# MK22FA12 register map
Vendor: Freescale Semiconductor, Inc.; Series: Kinetis_K; File version: 1.6
CPU: CM4 r0p1, little endian, no MPU, FPU, VTOR, 4 interrupt priority bits
Registers are 32-bit, read-write, reset 0x0 unless marked. A register's access mark holds for its fields unless they carry their own. Offsets are from the block's base; [hi:lo] are bit positions; {n}, {i} and the like mark numbered series; 'fields as' and 'values as' point back to an identical list.

## SPI0 — Serial Peripheral Interface
Base 0x4002C000; register names take the prefix SPI0_
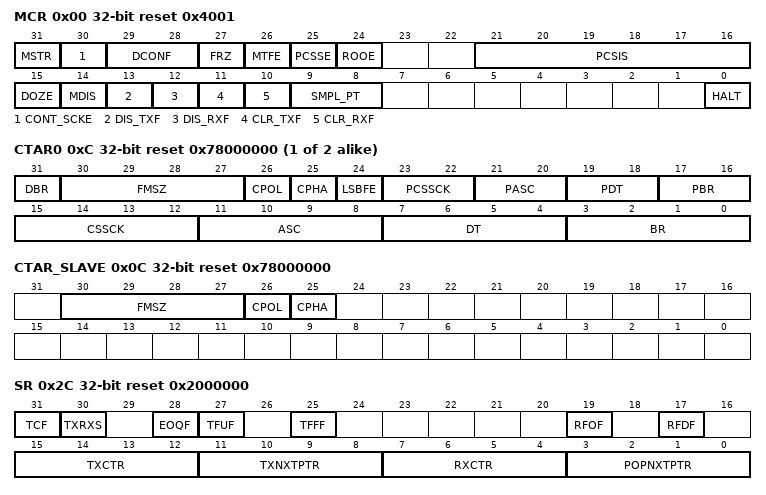
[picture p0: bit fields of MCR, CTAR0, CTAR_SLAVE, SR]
0x00 MCR reset 0x4001 — Module Configuration Register
  [31] MSTR — Master/Slave Mode Select
    0=Enables Slave mode; 1=Enables Master mode
  [30] CONT_SCKE — Continuous SCK Enable
    0=Continuous SCK disabled; 1=Continuous SCK enabled
  [29:28] DCONF ro — SPI Configuration.
    0=SPI
  [27] FRZ — Freeze
    0=Do not halt serial transfers in Debug mode; 1=Halt serial transfers in Debug mode
  [26] MTFE — Modified Timing Format Enable
    0=Modified SPI transfer format disabled; 1=Modified SPI transfer format enabled
  [25] PCSSE — Peripheral Chip Select Strobe Enable
    0=PCS5/ PCSS is used as the Peripheral Chip Select[5] signal; 1=PCS5/ PCSS is used as an active-low PCS Strobe signal
  [24] ROOE — Receive FIFO Overflow Overwrite Enable
    0=Incoming data is ignored; 1=Incoming data is shifted into the shift register
  [21:16] PCSIS — Peripheral Chip Select x Inactive State
    0=The inactive state of PCSx is low; 1=The inactive state of PCSx is high
  [15] DOZE — Doze Enable
    0=Doze mode has no effect on the module; 1=Doze mode disables the module
  [14] MDIS — Module Disable
    0=Enables the module clocks; 1=Allows external logic to disable the module clocks
  [13] DIS_TXF — Disable Transmit FIFO
    0=TX FIFO is enabled; 1=TX FIFO is disabled
  [12] DIS_RXF — Disable Receive FIFO
    0=RX FIFO is enabled; 1=RX FIFO is disabled
  [11] CLR_TXF wo — Clear TX FIFO
    0=Do not clear the TX FIFO counter; 1=Clear the TX FIFO counter
  [10] CLR_RXF wo
    0=Do not clear the RX FIFO counter; 1=Clear the RX FIFO counter
  [9:8] SMPL_PT — Sample Point
    0=0 protocol clock cycles between SCK edge and SIN sample; 1=1 protocol clock cycle between SCK edge and SIN sample; 2=2 protocol clock cycles between SCK edge and SIN sample
  [0] HALT
    0=Start transfers; 1=Stop transfers
0x08 TCR — Transfer Count Register
  [31:16] SPI_TCNT — SPI Transfer Counter
{0xC+4i} CTAR{i} (i=0..1) reset 0x78000000 (SPI0 view) — Clock and Transfer Attributes Register (In Master Mode)
  [31] DBR — Double Baud Rate
    0=The baud rate is computed normally with a 50/50 duty cycle; 1=The baud rate is doubled with the duty cycle depending on the Baud Rate Prescaler
  [30:27] FMSZ — Frame Size
  [26] CPOL — Clock Polarity
    0=The inactive state value of SCK is low; 1=The inactive state value of SCK is high
  [25] CPHA — Clock Phase
    0=Data is captured on the leading edge of SCK and changed on the following edge; 1=Data is changed on the leading edge of SCK and captured on the following edge
  [24] LSBFE — LSB First
    0=Data is transferred MSB first; 1=Data is transferred LSB first
  [23:22] PCSSCK — PCS to SCK Delay Prescaler
    0=PCS to SCK Prescaler value is 1; 1=PCS to SCK Prescaler value is 3; 2=PCS to SCK Prescaler value is 5; 3=PCS to SCK Prescaler value is 7
  [21:20] PASC — After SCK Delay Prescaler
    0=Delay after Transfer Prescaler value is 1; 1=Delay after Transfer Prescaler value is 3; 2=Delay after Transfer Prescaler value is 5; 3=Delay after Transfer Prescaler value is 7
  [19:18] PDT — Delay after Transfer Prescaler
    values as PASC
  [17:16] PBR — Baud Rate Prescaler
    0=Baud Rate Prescaler value is 2; 1=Baud Rate Prescaler value is 3; 2=Baud Rate Prescaler value is 5; 3=Baud Rate Prescaler value is 7
  [15:12] CSSCK — PCS to SCK Delay Scaler
  [11:8] ASC — After SCK Delay Scaler
  [7:4] DT — Delay After Transfer Scaler
  [3:0] BR — Baud Rate Scaler
0x0C CTAR_SLAVE reset 0x78000000 (SPI0 view) — Clock and Transfer Attributes Register (In Slave Mode)
  [30:27] FMSZ — Frame Size
  [26] CPOL — Clock Polarity
    values as CTAR0.CPOL
  [25] CPHA — Clock Phase
    values as CTAR0.CPHA
0x2C SR reset 0x2000000 — Status Register
  [31] TCF — Transfer Complete Flag
    0=Transfer not complete; 1=Transfer complete
  [30] TXRXS — TX and RX Status
    0=Transmit and receive operations are disabled (The module is in Stopped state); 1=Transmit and receive operations are enabled (The module is in Running state)
  [28] EOQF — End of Queue Flag
    0=EOQ is not set in the executing command; 1=EOQ is set in the executing SPI command
  [27] TFUF — Transmit FIFO Underflow Flag
    0=No TX FIFO underflow; 1=TX FIFO underflow has occurred
  [25] TFFF — Transmit FIFO Fill Flag
    0=TX FIFO is full; 1=TX FIFO is not full
  [19] RFOF — Receive FIFO Overflow Flag
    0=No Rx FIFO overflow; 1=Rx FIFO overflow has occurred
  [17] RFDF — Receive FIFO Drain Flag
    0=RX FIFO is empty; 1=RX FIFO is not empty
  [15:12] TXCTR ro — TX FIFO Counter
  [11:8] TXNXTPTR ro — Transmit Next Pointer
  [7:4] RXCTR ro — RX FIFO Counter
  [3:0] POPNXTPTR ro — Pop Next Pointer
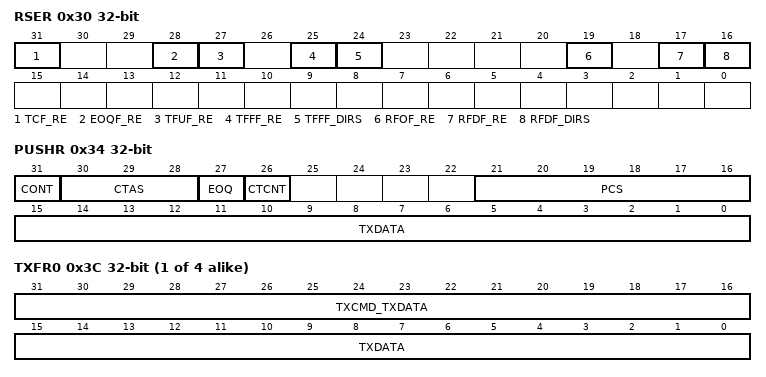
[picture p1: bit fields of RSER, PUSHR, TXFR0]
0x30 RSER — DMA/Interrupt Request Select and Enable Register
  [31] TCF_RE — Transmission Complete Request Enable
    0=TCF interrupt requests are disabled; 1=TCF interrupt requests are enabled
  [28] EOQF_RE — Finished Request Enable
    0=EOQF interrupt requests are disabled; 1=EOQF interrupt requests are enabled
  [27] TFUF_RE — Transmit FIFO Underflow Request Enable
    0=TFUF interrupt requests are disabled; 1=TFUF interrupt requests are enabled
  [25] TFFF_RE — Transmit FIFO Fill Request Enable
    0=TFFF interrupts or DMA requests are disabled; 1=TFFF interrupts or DMA requests are enabled
  [24] TFFF_DIRS — Transmit FIFO Fill DMA or Interrupt Request Select
    0=TFFF flag generates interrupt requests; 1=TFFF flag generates DMA requests
  [19] RFOF_RE — Receive FIFO Overflow Request Enable
    0=RFOF interrupt requests are disabled; 1=RFOF interrupt requests are enabled
  [17] RFDF_RE — Receive FIFO Drain Request Enable
    0=RFDF interrupt or DMA requests are disabled; 1=RFDF interrupt or DMA requests are enabled
  [16] RFDF_DIRS — Receive FIFO Drain DMA or Interrupt Request Select
    0=Interrupt request; 1=DMA request
0x34 PUSHR (SPI0 view) — PUSH TX FIFO Register In Master Mode
  [31] CONT — Continuous Peripheral Chip Select Enable
    0=Return PCSn signals to their inactive state between transfers; 1=Keep PCSn signals asserted between transfers
  [30:28] CTAS — Clock and Transfer Attributes Select
    0=CTAR0; 1=CTAR1
  [27] EOQ — End Of Queue
    0=The SPI data is not the last data to transfer; 1=The SPI data is the last data to transfer
  [26] CTCNT — Clear Transfer Counter
    0=Do not clear the TCR[TCNT] field; 1=Clear the TCR[TCNT] field
  [21:16] PCS — Select which PCS signals are to be asserted for the transfer
    0=Negate the PCS[x] signal; 1=Assert the PCS[x] signal
  [15:0] TXDATA — Transmit Data
0x34 PUSHR_SLAVE (SPI0 view) — PUSH TX FIFO Register In Slave Mode
  [31:0] TXDATA — Transmit Data
0x38 POPR ro — POP RX FIFO Register
  [31:0] RXDATA — Received Data
{0x3C+4i} TXFR{i} (i=0..3) ro — Transmit FIFO Registers
  [31:16] TXCMD_TXDATA — Transmit Command or Transmit Data
  [15:0] TXDATA — Transmit Data
{0x7C+4i} RXFR{i} (i=0..3) ro — Receive FIFO Registers
  [31:0] RXDATA — Receive Data

## SPI1 — Serial Peripheral Interface
Base 0x4002D000; register names take the prefix SPI1_
Registers as SPI0 (with SPI0 read as SPI1).

## SPI2 — Serial Peripheral Interface
Base 0x400AC000; register names take the prefix SPI2_
Registers as SPI0 (with SPI0 read as SPI2).
